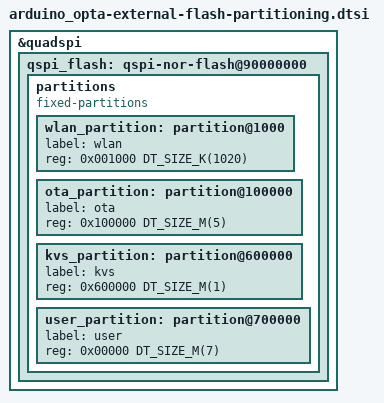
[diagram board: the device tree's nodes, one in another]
/*
 * Copyright (c) 2024 DNDG srl
 *
 * SPDX-License-Identifier: Apache-2.0
 */

&quadspi {
	qspi_flash: qspi-nor-flash@90000000 {

		/delete-node/ partitions;

		partitions {
			compatible = "fixed-partitions";
			#address-cells = <1>;
			#size-cells = <1>;

			/* Partition 1: WiFi firmware and certificates 1MB - 4kB */
			wlan_partition: partition@1000 {
				label = "wlan";
				reg = <0x001000 DT_SIZE_K(1020)>;
			};

			/* Partition 2: OTA 5MB */
			ota_partition: partition@100000 {
				label = "ota";
				reg = <0x100000 DT_SIZE_M(5)>;
			};

			/* Partition 3: Provisioning KVStore 1MB */
			kvs_partition: partition@600000 {
				label = "kvs";
				reg = <0x600000 DT_SIZE_M(1)>;
			};

			/* Partition 4: User data / OPTA PLC runtime 7MB (littlefs) */
			user_partition: partition@700000 {
				label = "user";
				reg = <0x00000 DT_SIZE_M(7)>;
			};
		};
	};
};
